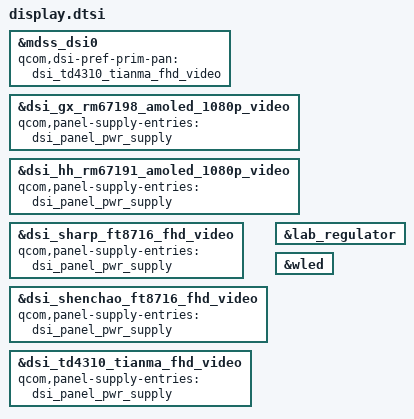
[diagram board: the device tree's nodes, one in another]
/* Display panels */
#include "panel/dsi-panel-gx_rm67198_amoled_1080p_video.dtsi"
#include "panel/dsi-panel-hh_rm67191_amoled_1080p_video.dtsi"
#include "panel/dsi-panel-sharp_ft8716_fhd_video.dtsi"
#include "panel/dsi-panel-shenchao_ft8716_fhd_video.dtsi"
#include "panel/dsi-panel-td4310_tianma_fhd_video.dtsi"

&mdss_dsi0 {
	qcom,dsi-pref-prim-pan = <&dsi_td4310_tianma_fhd_video>;
};

&dsi_gx_rm67198_amoled_1080p_video {
	qcom,panel-supply-entries = <&dsi_panel_pwr_supply>;
};

&dsi_hh_rm67191_amoled_1080p_video {
	qcom,panel-supply-entries = <&dsi_panel_pwr_supply>;
};

&dsi_sharp_ft8716_fhd_video {
	qcom,panel-supply-entries = <&dsi_panel_pwr_supply>;
};

&dsi_shenchao_ft8716_fhd_video {
	qcom,panel-supply-entries = <&dsi_panel_pwr_supply>;
};

&dsi_td4310_tianma_fhd_video {
	qcom,panel-supply-entries = <&dsi_panel_pwr_supply>;
};

/* msm-pmi8950.dtsi */
&lab_regulator {
	/delete-property/ qcom,qpnp-lab-ps-enable;
};
&wled {
	/delete-property/ qcom,en-ext-pfet-sc-pro;
};

/* msm8953-mtp.dtsi */
&mdss_dsi0 {
	/delete-property/ qcom,platform-bklight-en-gpio;
};
